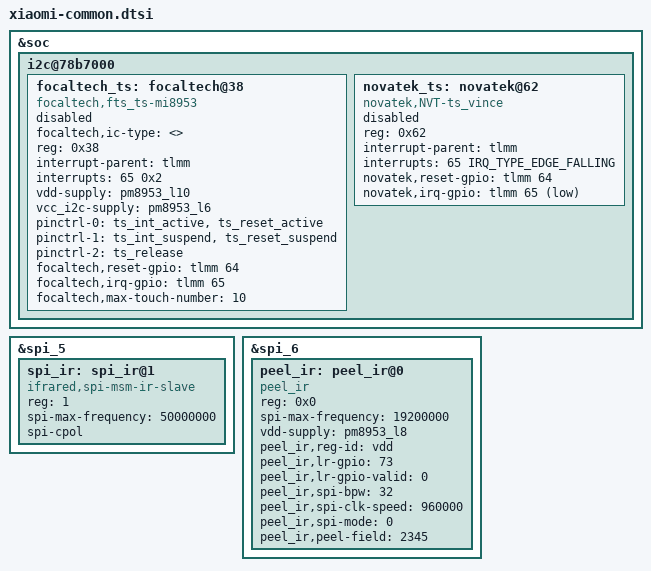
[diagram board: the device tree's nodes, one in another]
&soc { 
	i2c@78b7000 { /* BLSP1 QUP3 */
		status = "okay";

        focaltech_ts: focaltech@38{
		    compatible = "focaltech,fts_ts-mi8953";
		    focaltech,ic-type = <>; // Unknown
		    reg = <0x38>;
		    interrupt-parent = <&tlmm>;
		    interrupts = <65 0x2>;

            status = "disabled";

		    vdd-supply = <&pm8953_l10>;
		    vcc_i2c-supply = <&pm8953_l6>;
		    /* pins used by touchscreen */
                        pinctrl-names = "pmx_ts_active","pmx_ts_suspend",
                                                        "pmx_ts_release";
                        pinctrl-0 = <&ts_int_active &ts_reset_active>;
                        pinctrl-1 = <&ts_int_suspend &ts_reset_suspend>;
                        pinctrl-2 = <&ts_release>;
		    focaltech,reset-gpio = <&tlmm 64 0x00>;
		    focaltech,irq-gpio = <&tlmm 65 0x02>;
		    focaltech,max-touch-number = <10>;
	    };

		novatek_ts: novatek@62 {
			compatible = "novatek,NVT-ts_vince";
			reg = <0x62>;
			interrupt-parent = <&tlmm>;
			interrupts = <65 IRQ_TYPE_EDGE_FALLING>;

            status = "disabled";

			novatek,reset-gpio = <&tlmm 64 0x0>;
			novatek,irq-gpio = <&tlmm 65 0x2001>;
		};
	};
};

&spi_5 {
	spi_ir: spi_ir@1 {
	    compatible = "ifrared,spi-msm-ir-slave";
	    reg = <1>; /* Chip select 0 */
	    spi-max-frequency = <50000000>;
	    spi-cpol;
	};
};

&spi_6 {
	peel_ir: peel_ir@0 {
		compatible = "peel_ir";
		reg = <0x0>;
		spi-max-frequency = <19200000>;
		vdd-supply = <&pm8953_l8>; //vdd
		peel_ir,reg-id = "vdd";
		peel_ir,lr-gpio = <73>;
		peel_ir,lr-gpio-valid = <0>;
		peel_ir,spi-bpw = <32>;
		peel_ir,spi-clk-speed = <960000>;
		peel_ir,spi-mode = <0>;
		peel_ir,peel-field = <2345>;
	};
};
